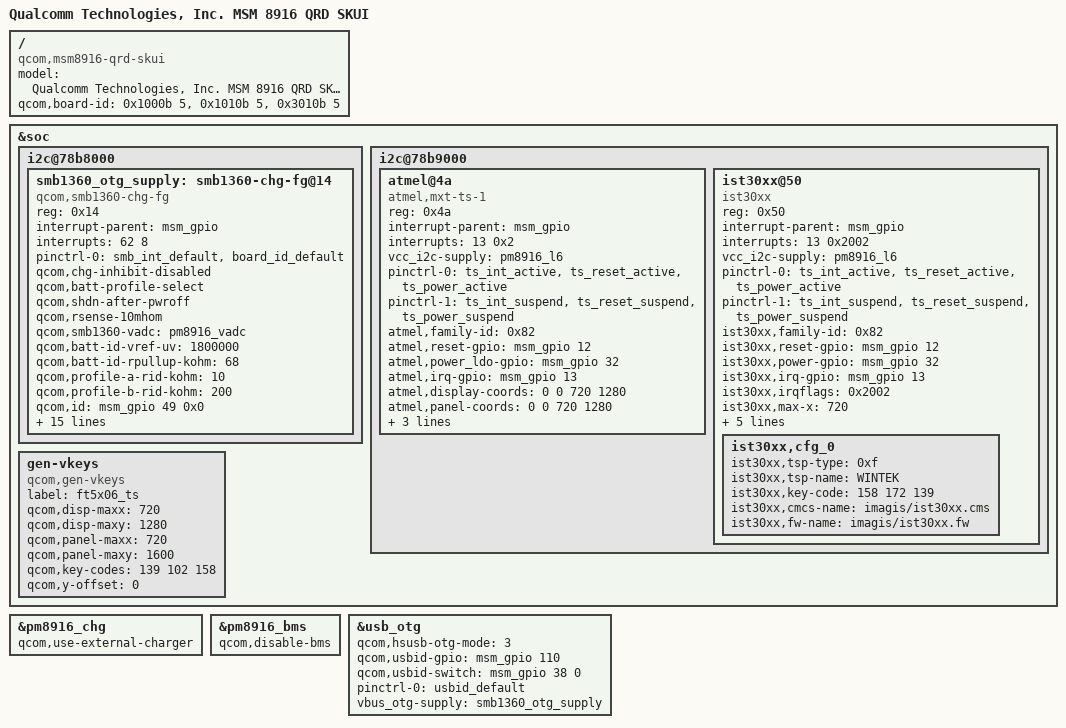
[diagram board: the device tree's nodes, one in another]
/* Copyright (c) 2014, The Linux Foundation. All rights reserved.
 *
 * This program is free software; you can redistribute it and/or modify
 * it under the terms of the GNU General Public License version 2 and
 * only version 2 as published by the Free Software Foundation.
 *
 * This program is distributed in the hope that it will be useful,
 * but WITHOUT ANY WARRANTY; without even the implied warranty of
 * MERCHANTABILITY or FITNESS FOR A PARTICULAR PURPOSE.  See the
 * GNU General Public License for more details.
 */

/dts-v1/;

#include "msm8916-qrd-skui.dtsi"
#include "msm8916-memory.dtsi"

/ {
	model = "Qualcomm Technologies, Inc. MSM 8916 QRD SKUI";
	compatible = "qcom,msm8916-qrd-skui", "qcom,msm8916-qrd", "qcom,msm8916", "qcom,qrd";
	qcom,board-id = <0x1000b 5> , <0x1010b 5> , <0x3010b 5>;
};

&soc {
	i2c@78b8000 {
		smb1360_otg_supply: smb1360-chg-fg@14 {
			compatible = "qcom,smb1360-chg-fg";
			reg = <0x14>;
			interrupt-parent = <&msm_gpio>;
			interrupts = <62 8>;
			pinctrl-names = "default";
			pinctrl-0 = <&smb_int_default &board_id_default>;
			qcom,chg-inhibit-disabled;

			qcom,batt-profile-select;
			qcom,shdn-after-pwroff;
			qcom,rsense-10mhom;
			qcom,smb1360-vadc = <&pm8916_vadc>;
			qcom,batt-id-vref-uv = <1800000>;
			qcom,batt-id-rpullup-kohm = <68>;
			qcom,profile-a-rid-kohm = <10>;
			qcom,profile-b-rid-kohm = <200>;
			qcom,id = <&msm_gpio 49 0x0>;
			qcom,fg-batt-capacity-mah = <3100>;
			qcom,fg-cc-soc-coeff = <0x8149>;
			qcom,fg-delta-soc = <1>;
			qcom,fg-cutoff-voltage-mv = <3400>;
			qcom,fg-iterm-ma = <100>;
			qcom,fg-ibatt-standby-ma = <200>;
			qcom,fg-cc-to-cv-mv = <4328>;
			qcom,thermistor-c1-coeff = <0x85D2>;

			qcom,float-voltage-mv = <4350>;
			qcom,iterm-ma = <100>;
			qcom,otg-batt-curr-limit = <1500>;
			qcom,recharge-thresh-mv = <100>;
			qcom,thermal-mitigation = <1500 700 600 0>;
			qcom,fg-auto-recharge-soc = <99>;
			regulator-name = "smb1360_otg_vreg";
		};
	};

	i2c@78b9000 { /* BLSP1 QUP5 */
		atmel@4a{
			compatible = "atmel,mxt-ts-1";
			reg = <0x4a>;
			interrupt-parent = <&msm_gpio>;
			interrupts = <13 0x2>;
			vcc_i2c-supply = <&pm8916_l6>;
			/* pins used by touchscreen */
			pinctrl-names = "pmx_ts_active","pmx_ts_suspend";
			pinctrl-0 = <&ts_int_active &ts_reset_active &ts_power_active>;
			pinctrl-1 = <&ts_int_suspend &ts_reset_suspend &ts_power_suspend>;
			atmel,family-id = <0x82>;
			atmel,reset-gpio = <&msm_gpio 12 0x0>;
			atmel,power_ldo-gpio = <&msm_gpio 32 0x0>;
			atmel,irq-gpio = <&msm_gpio 13 0x2008>; //IRQF_TRIGGER_LOW
			atmel,display-coords = <0 0 720 1280>;
			atmel,panel-coords = <0 0 720 1280>;
			atmel,button-map= <158 102 139>;
			atmel,no-force-update;
			atmel,i2c-pull-up;
		};
        ist30xx@50{
			compatible = "ist30xx";
			reg = <0x50>;
			interrupt-parent = <&msm_gpio>;
			interrupts = <13 0x2002>;
			vcc_i2c-supply = <&pm8916_l6>;

			pinctrl-names = "pmx_ts_active","pmx_ts_suspend";
			pinctrl-0 = <&ts_int_active &ts_reset_active &ts_power_active>;
			pinctrl-1 = <&ts_int_suspend &ts_reset_suspend &ts_power_suspend>;
			ist30xx,family-id = <0x82>;
			ist30xx,reset-gpio = <&msm_gpio 12 0x0>;
			ist30xx,power-gpio = <&msm_gpio 32 0x0>;
			ist30xx,irq-gpio = <&msm_gpio 13 0x2002>;
			ist30xx,irqflags = <0x2002>;
			ist30xx,max-x = <720>;
			ist30xx,max-y = <1280>;
			ist30xx,max-w = <200>;
			ist30xx,key-num = <3>;
			ist30xx,config-array-size = <1>;
			ist30xx,i2c-pull-up;
			ist30xx,cfg_0{
			ist30xx,tsp-type = <0xf>;
			ist30xx,tsp-name = "WINTEK";
			ist30xx,key-code = <158 172 139>;
			ist30xx,cmcs-name = "imagis/ist30xx.cms";
			ist30xx,fw-name = "imagis/ist30xx.fw";
			};
		};
	};

	gen-vkeys {
		compatible = "qcom,gen-vkeys";
		label = "ft5x06_ts";
		qcom,disp-maxx = <720>;
		qcom,disp-maxy = <1280>;
		qcom,panel-maxx = <720>;
		qcom,panel-maxy = <1600>;
		qcom,key-codes = <139 102 158>;
		qcom,y-offset = <0>;
	};
};

&pm8916_chg {
	status = "ok";
	qcom,use-external-charger;
};

&pm8916_bms {
	status = "ok";
	qcom,disable-bms;
};

&usb_otg {
	qcom,hsusb-otg-mode = <3>;
	qcom,usbid-gpio = <&msm_gpio 110 0>;
	qcom,usbid-switch = <&msm_gpio 38 0>;
	pinctrl-names = "default";
	pinctrl-0 = <&usbid_default>;
	vbus_otg-supply = <&smb1360_otg_supply>;
};
